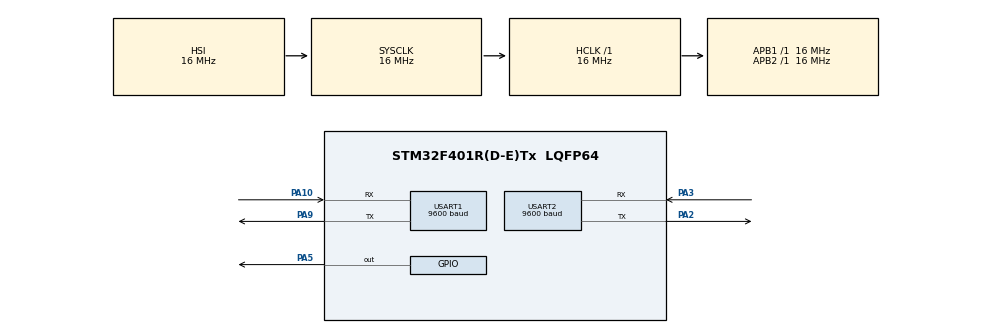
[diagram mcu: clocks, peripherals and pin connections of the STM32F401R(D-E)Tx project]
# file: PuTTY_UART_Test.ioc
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FREERTOS.Tasks01=defaultTask,24,128,StartDefaultTask,Default,NULL,Dynamic,NULL,NULL
FREERTOS.configUSE_NEWLIB_REENTRANT=1
Mcu.Family=STM32F4
Mcu.Name=STM32F401R(D-E)Tx
Mcu.Package=LQFP64
NVIC.PriorityGroup=NVIC_PRIORITYGROUP_4
NVIC.TIM5_IRQn=true\:15\:0\:false\:false\:true\:false\:false\:true\:true
NVIC.TimeBase=TIM5_IRQn
NVIC.TimeBaseIP=TIM5
PA10.Mode=Asynchronous
PA10.Signal=USART1_RX
PA2.Mode=Asynchronous
PA2.Signal=USART2_TX
PA3.Mode=Asynchronous
PA3.Signal=USART2_RX
PA5.Signal=GPIO_Output
PA9.Mode=Asynchronous
PA9.Signal=USART1_TX
ProjectManager.HeapSize=0x200
ProjectManager.StackSize=0x400
ProjectManager.TargetToolchain=STM32CubeIDE
RCC.AHBFreq_Value=16000000
RCC.APB1Freq_Value=16000000
RCC.APB2Freq_Value=16000000
RCC.CortexFreq_Value=16000000
RCC.HSE_VALUE=25000000
RCC.HSI_VALUE=16000000
RCC.LSE_VALUE=32768
RCC.SYSCLKFreq_VALUE=16000000
RCC.VCOOutputFreq_Value=192000000
USART1.BaudRate=9600
USART1.VirtualMode=VM_ASYNC
USART2.BaudRate=9600
USART2.VirtualMode=VM_ASYNC
VP_FREERTOS_VS_CMSIS_V2.Mode=CMSIS_V2
VP_SYS_VS_tim5.Mode=TIM5
board=custom

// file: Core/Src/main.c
/* USER CODE BEGIN Header */
/**
  ******************************************************************************
  * @file           : main.c
  * @brief          : Main program body
  ******************************************************************************
  * @attention
  *
  * Copyright (c) 2026 STMicroelectronics.
  * All rights reserved.
  *
  * This software is licensed under terms that can be found in the LICENSE file
  * in the root directory of this software component.
  * If no LICENSE file comes with this software, it is provided AS-IS.
  *
  ******************************************************************************
  */
/* USER CODE END Header */
#include "main.h"
#include "cmsis_os.h"

/* USER CODE BEGIN Includes */
#include "string.h"
#include <stdio.h>
/* USER CODE END Includes */

UART_HandleTypeDef huart1;
UART_HandleTypeDef huart2;

/* Definitions for defaultTask */
osThreadId_t defaultTaskHandle;
const osThreadAttr_t defaultTask_attributes = {
  .name = "defaultTask",
  .stack_size = 128 * 4,
  .priority = (osPriority_t) osPriorityNormal,
};
/* USER CODE BEGIN PV */
uint8_t rxByte;
/* USER CODE END PV */

void SystemClock_Config(void);
static void MX_GPIO_Init(void);
static void MX_USART1_UART_Init(void);
static void MX_USART2_UART_Init(void);
void StartDefaultTask(void *argument);

int main(void)
{

  /* MCU Configuration--------------------------------------------------------*/

  /* Reset of all peripherals, Initializes the Flash interface and the Systick. */
  HAL_Init();

  /* Configure the system clock */
  SystemClock_Config();

  /* Initialize all configured peripherals */
  MX_GPIO_Init();
  MX_USART1_UART_Init();
  MX_USART2_UART_Init();

  /* Init scheduler */
  osKernelInitialize();

  /* Create the thread(s) */
  /* creation of defaultTask */
  defaultTaskHandle = osThreadNew(StartDefaultTask, NULL, &defaultTask_attributes);

  /* Start scheduler */
  osKernelStart();

  /* We should never get here as control is now taken by the scheduler */

  /* Infinite loop */
  while (1)
  {

  }
}

void SystemClock_Config(void)
{
  RCC_OscInitTypeDef RCC_OscInitStruct = {0};
  RCC_ClkInitTypeDef RCC_ClkInitStruct = {0};

  /** Configure the main internal regulator output voltage
  */
  __HAL_RCC_PWR_CLK_ENABLE();
  __HAL_PWR_VOLTAGESCALING_CONFIG(PWR_REGULATOR_VOLTAGE_SCALE2);

  /** Initializes the RCC Oscillators according to the specified parameters
  * in the RCC_OscInitTypeDef structure.
  */
  RCC_OscInitStruct.OscillatorType = RCC_OSCILLATORTYPE_HSI;
  RCC_OscInitStruct.HSIState = RCC_HSI_ON;
  RCC_OscInitStruct.HSICalibrationValue = RCC_HSICALIBRATION_DEFAULT;
  RCC_OscInitStruct.PLL.PLLState = RCC_PLL_NONE;
  if (HAL_RCC_OscConfig(&RCC_OscInitStruct) != HAL_OK)
  {
    Error_Handler();
  }

  /** Initializes the CPU, AHB and APB buses clocks
  */
  RCC_ClkInitStruct.ClockType = RCC_CLOCKTYPE_HCLK|RCC_CLOCKTYPE_SYSCLK
                              |RCC_CLOCKTYPE_PCLK1|RCC_CLOCKTYPE_PCLK2;
  RCC_ClkInitStruct.SYSCLKSource = RCC_SYSCLKSOURCE_HSI;
  RCC_ClkInitStruct.AHBCLKDivider = RCC_SYSCLK_DIV1;
  RCC_ClkInitStruct.APB1CLKDivider = RCC_HCLK_DIV1;
  RCC_ClkInitStruct.APB2CLKDivider = RCC_HCLK_DIV1;

  if (HAL_RCC_ClockConfig(&RCC_ClkInitStruct, FLASH_LATENCY_0) != HAL_OK)
  {
    Error_Handler();
  }
}

static void MX_USART1_UART_Init(void)
{

  huart1.Instance = USART1;
  huart1.Init.BaudRate = 9600;
  huart1.Init.WordLength = UART_WORDLENGTH_8B;
  huart1.Init.StopBits = UART_STOPBITS_1;
  huart1.Init.Parity = UART_PARITY_NONE;
  huart1.Init.Mode = UART_MODE_TX_RX;
  huart1.Init.HwFlowCtl = UART_HWCONTROL_NONE;
  huart1.Init.OverSampling = UART_OVERSAMPLING_16;
  if (HAL_UART_Init(&huart1) != HAL_OK)
  {
    Error_Handler();
  }

}

static void MX_USART2_UART_Init(void)
{

  huart2.Instance = USART2;
  huart2.Init.BaudRate = 9600;
  huart2.Init.WordLength = UART_WORDLENGTH_8B;
  huart2.Init.StopBits = UART_STOPBITS_1;
  huart2.Init.Parity = UART_PARITY_NONE;
  huart2.Init.Mode = UART_MODE_TX_RX;
  huart2.Init.HwFlowCtl = UART_HWCONTROL_NONE;
  huart2.Init.OverSampling = UART_OVERSAMPLING_16;
  if (HAL_UART_Init(&huart2) != HAL_OK)
  {
    Error_Handler();
  }

}

static void MX_GPIO_Init(void)
{
  GPIO_InitTypeDef GPIO_InitStruct = {0};

  /* GPIO Ports Clock Enable */
  __HAL_RCC_GPIOA_CLK_ENABLE();

  /*Configure GPIO pin Output Level */
  HAL_GPIO_WritePin(GPIOA, GPIO_PIN_5, GPIO_PIN_RESET);

  /*Configure GPIO pin : PA5 */
  GPIO_InitStruct.Pin = GPIO_PIN_5;
  GPIO_InitStruct.Mode = GPIO_MODE_OUTPUT_PP;
  GPIO_InitStruct.Pull = GPIO_NOPULL;
  GPIO_InitStruct.Speed = GPIO_SPEED_FREQ_LOW;
  HAL_GPIO_Init(GPIOA, &GPIO_InitStruct);

}

void StartDefaultTask(void *argument)
{
  /* USER CODE BEGIN 5 */
	char msgg[] = "Hello from FreeRTOS";
	//uint32_t count = 0;
	//char buf[40];
	uint8_t ch;
	char *msg = "STM UART LOOPBACK TEST===\n"
			"type and it will echo back";
	HAL_UART_Transmit(&huart2, (uint8_t*)msg, strlen(msg), 500);
  /* Infinite loop */
  for(;;)
  {
    //HAL_GPIO_TogglePin(GPIOA, GPIO_PIN_5);
    //vTaskDelay(pdMS_TO_TICKS(100));
    //count++;
    //snprintf(buf,sizeof(buf),"Tick #%lu - Hello!\r\n",count);
    //HAL_UART_Transmit(&huart2, (uint8_t*)buf, strlen(buf), 100);
    //vTaskDelay(pdMS_TO_TICKS(100));
	  HAL_UART_Transmit(&huart2, (uint8_t*)msgg, strlen(msgg), 100);

	  if(HAL_UART_Receive(&huart2, &ch, 1, HAL_MAX_DELAY)==HAL_OK)
	  {
		  HAL_UART_Transmit(&huart1, &ch, 1, 100);
		  if(ch=='\r')
		  {
			  uint8_t nl = '\n';
			  HAL_UART_Transmit(&huart1, &nl, 1, 100);
		  }
	  }
  }
  /* USER CODE END 5 */
}

void HAL_TIM_PeriodElapsedCallback(TIM_HandleTypeDef *htim)
{
  if (htim->Instance == TIM5)
  {
    HAL_IncTick();
  }
}

void Error_Handler(void)
{
  __disable_irq();
  while (1)
  {
  }
}
